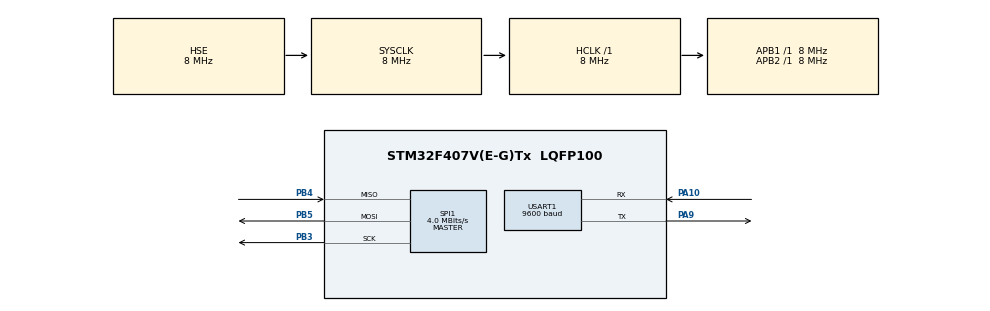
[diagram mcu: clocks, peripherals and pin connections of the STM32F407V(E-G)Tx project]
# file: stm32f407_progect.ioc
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Mcu.Family=STM32F4
Mcu.Name=STM32F407V(E-G)Tx
Mcu.Package=LQFP100
NVIC.PriorityGroup=NVIC_PRIORITYGROUP_4
NVIC.USART1_IRQn=true\:0\:0\:false\:false\:true\:true\:true
PA10.Mode=Asynchronous
PA10.Signal=USART1_RX
PA9.GPIO_PuPd=GPIO_PULLUP
PA9.Mode=Asynchronous
PA9.Signal=USART1_TX
PB3.Mode=Full_Duplex_Master
PB3.Signal=SPI1_SCK
PB4.Mode=Full_Duplex_Master
PB4.Signal=SPI1_MISO
PB5.Mode=Full_Duplex_Master
PB5.Signal=SPI1_MOSI
PC14-OSC32_IN.Mode=LSE-External-Oscillator
PC14-OSC32_IN.Signal=RCC_OSC32_IN
PC15-OSC32_OUT.Mode=LSE-External-Oscillator
PC15-OSC32_OUT.Signal=RCC_OSC32_OUT
PH0-OSC_IN.Mode=HSE-External-Oscillator
PH0-OSC_IN.Signal=RCC_OSC_IN
PH1-OSC_OUT.Mode=HSE-External-Oscillator
PH1-OSC_OUT.Signal=RCC_OSC_OUT
ProjectManager.HeapSize=0x200
ProjectManager.StackSize=0x1000
ProjectManager.TargetToolchain=MDK-ARM V5.27
RCC.48MHZClocksFreq_Value=24000000
RCC.AHBFreq_Value=8000000
RCC.APB1Freq_Value=8000000
RCC.APB1TimFreq_Value=8000000
RCC.APB2Freq_Value=8000000
RCC.APB2TimFreq_Value=8000000
RCC.CortexFreq_Value=8000000
RCC.HCLKFreq_Value=8000000
RCC.HSE_VALUE=8000000
RCC.HSI_VALUE=16000000
RCC.PLLSourceVirtual=RCC_PLLSOURCE_HSE
RCC.RCC_RTC_Clock_Source=RCC_RTCCLKSOURCE_LSE
RCC.RCC_RTC_Clock_SourceVirtual=RCC_RTCCLKSOURCE_LSE
RCC.SYSCLKFreq_VALUE=8000000
RCC.SYSCLKSource=RCC_SYSCLKSOURCE_HSE
RCC.VCOOutputFreq_Value=96000000
SPI1.CalculateBaudRate=4.0 MBits/s
SPI1.Direction=SPI_DIRECTION_2LINES
SPI1.Mode=SPI_MODE_MASTER
SPI1.VirtualType=VM_MASTER
USART1.BaudRate=9600
USART1.VirtualMode=VM_ASYNC
VP_RTC_VS_RTC_Activate.Mode=RTC_Enabled
VP_RTC_VS_RTC_Calendar.Mode=RTC_Calendar
board=custom

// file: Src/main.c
/* USER CODE BEGIN Header */
/**
  ******************************************************************************
  * @file           : main.c
  * @brief          : Main program body
  ******************************************************************************
  * @attention
  *
  * <h2><center>&copy; Copyright (c) 2020 STMicroelectronics.
  * All rights reserved.</center></h2>
  *
  * This software component is licensed by ST under BSD 3-Clause license,
  * the "License"; You may not use this file except in compliance with the
  * License. You may obtain a copy of the License at:
  *                        opensource.org/licenses/BSD-3-Clause
  *
  ******************************************************************************
  */
/* USER CODE END Header */

#include "main.h"

RTC_HandleTypeDef hrtc;

SPI_HandleTypeDef hspi1;

UART_HandleTypeDef huart1;

void SystemClock_Config(void);
static void MX_GPIO_Init(void);
static void MX_RTC_Init(void);
static void MX_SPI1_Init(void);
static void MX_USART1_UART_Init(void);

/* USER CODE BEGIN 0 */
void delay_ms(int32_t nms)
 {
  int32_t temp;
  SysTick->LOAD = 8000*nms;
  SysTick->VAL=0X00;//清空计数器
  SysTick->CTRL=0X01;//使能，减到零是无动作，采用外部时钟源
  do
  {
       temp=SysTick->CTRL;//读取当前倒计数值
  }
     while((temp&0x01)&&(!(temp&(1<<16))));//等待时间到达

     SysTick->CTRL=0x00; //关闭计数器
     SysTick->VAL =0X00; //清空计数器
 }
/* USER CODE END 0 */

int main(void)
{
  /* USER CODE BEGIN 1 */
	uint8_t TxData[]= "Hello World!!!\n";
  /* USER CODE END 1 */

  /* MCU Configuration--------------------------------------------------------*/

  /* Reset of all peripherals, Initializes the Flash interface and the Systick. */
  HAL_Init();

  /* Configure the system clock */
  SystemClock_Config();

  /* Initialize all configured peripherals */
  MX_GPIO_Init();
  MX_RTC_Init();
  MX_SPI1_Init();
  MX_USART1_UART_Init();

  /* Infinite loop */
  /* USER CODE BEGIN WHILE */
  while (1)
  {
		HAL_UART_Transmit(&huart1,TxData,sizeof(TxData),0xffff);
		delay_ms(1000);
    /* USER CODE END WHILE */

  }
}

void SystemClock_Config(void)
{
  RCC_OscInitTypeDef RCC_OscInitStruct = {0};
  RCC_ClkInitTypeDef RCC_ClkInitStruct = {0};
  RCC_PeriphCLKInitTypeDef PeriphClkInitStruct = {0};

  /** Configure the main internal regulator output voltage
  */
  __HAL_RCC_PWR_CLK_ENABLE();
  __HAL_PWR_VOLTAGESCALING_CONFIG(PWR_REGULATOR_VOLTAGE_SCALE1);
  /** Initializes the CPU, AHB and APB busses clocks
  */
  RCC_OscInitStruct.OscillatorType = RCC_OSCILLATORTYPE_HSE|RCC_OSCILLATORTYPE_LSE;
  RCC_OscInitStruct.HSEState = RCC_HSE_ON;
  RCC_OscInitStruct.LSEState = RCC_LSE_ON;
  RCC_OscInitStruct.PLL.PLLState = RCC_PLL_NONE;
  if (HAL_RCC_OscConfig(&RCC_OscInitStruct) != HAL_OK)
  {
    Error_Handler();
  }
  /** Initializes the CPU, AHB and APB busses clocks
  */
  RCC_ClkInitStruct.ClockType = RCC_CLOCKTYPE_HCLK|RCC_CLOCKTYPE_SYSCLK
                              |RCC_CLOCKTYPE_PCLK1|RCC_CLOCKTYPE_PCLK2;
  RCC_ClkInitStruct.SYSCLKSource = RCC_SYSCLKSOURCE_HSE;
  RCC_ClkInitStruct.AHBCLKDivider = RCC_SYSCLK_DIV1;
  RCC_ClkInitStruct.APB1CLKDivider = RCC_HCLK_DIV1;
  RCC_ClkInitStruct.APB2CLKDivider = RCC_HCLK_DIV1;

  if (HAL_RCC_ClockConfig(&RCC_ClkInitStruct, FLASH_LATENCY_0) != HAL_OK)
  {
    Error_Handler();
  }
  PeriphClkInitStruct.PeriphClockSelection = RCC_PERIPHCLK_RTC;
  PeriphClkInitStruct.RTCClockSelection = RCC_RTCCLKSOURCE_LSE;
  if (HAL_RCCEx_PeriphCLKConfig(&PeriphClkInitStruct) != HAL_OK)
  {
    Error_Handler();
  }
}

static void MX_RTC_Init(void)
{

  RTC_TimeTypeDef sTime = {0};
  RTC_DateTypeDef sDate = {0};

  /** Initialize RTC Only
  */
  hrtc.Instance = RTC;
  hrtc.Init.HourFormat = RTC_HOURFORMAT_24;
  hrtc.Init.AsynchPrediv = 127;
  hrtc.Init.SynchPrediv = 255;
  hrtc.Init.OutPut = RTC_OUTPUT_DISABLE;
  hrtc.Init.OutPutPolarity = RTC_OUTPUT_POLARITY_HIGH;
  hrtc.Init.OutPutType = RTC_OUTPUT_TYPE_OPENDRAIN;
  if (HAL_RTC_Init(&hrtc) != HAL_OK)
  {
    Error_Handler();
  }

  /** Initialize RTC and set the Time and Date
  */
  sTime.Hours = 0x0;
  sTime.Minutes = 0x0;
  sTime.Seconds = 0x0;
  sTime.DayLightSaving = RTC_DAYLIGHTSAVING_NONE;
  sTime.StoreOperation = RTC_STOREOPERATION_RESET;
  if (HAL_RTC_SetTime(&hrtc, &sTime, RTC_FORMAT_BCD) != HAL_OK)
  {
    Error_Handler();
  }
  sDate.WeekDay = RTC_WEEKDAY_MONDAY;
  sDate.Month = RTC_MONTH_JANUARY;
  sDate.Date = 0x1;
  sDate.Year = 0x0;

  if (HAL_RTC_SetDate(&hrtc, &sDate, RTC_FORMAT_BCD) != HAL_OK)
  {
    Error_Handler();
  }

}

static void MX_SPI1_Init(void)
{

  /* SPI1 parameter configuration*/
  hspi1.Instance = SPI1;
  hspi1.Init.Mode = SPI_MODE_MASTER;
  hspi1.Init.Direction = SPI_DIRECTION_2LINES;
  hspi1.Init.DataSize = SPI_DATASIZE_8BIT;
  hspi1.Init.CLKPolarity = SPI_POLARITY_LOW;
  hspi1.Init.CLKPhase = SPI_PHASE_1EDGE;
  hspi1.Init.NSS = SPI_NSS_SOFT;
  hspi1.Init.BaudRatePrescaler = SPI_BAUDRATEPRESCALER_2;
  hspi1.Init.FirstBit = SPI_FIRSTBIT_MSB;
  hspi1.Init.TIMode = SPI_TIMODE_DISABLE;
  hspi1.Init.CRCCalculation = SPI_CRCCALCULATION_DISABLE;
  hspi1.Init.CRCPolynomial = 10;
  if (HAL_SPI_Init(&hspi1) != HAL_OK)
  {
    Error_Handler();
  }

}

static void MX_USART1_UART_Init(void)
{

  huart1.Instance = USART1;
  huart1.Init.BaudRate = 9600;
  huart1.Init.WordLength = UART_WORDLENGTH_8B;
  huart1.Init.StopBits = UART_STOPBITS_1;
  huart1.Init.Parity = UART_PARITY_NONE;
  huart1.Init.Mode = UART_MODE_TX_RX;
  huart1.Init.HwFlowCtl = UART_HWCONTROL_NONE;
  huart1.Init.OverSampling = UART_OVERSAMPLING_16;
  if (HAL_UART_Init(&huart1) != HAL_OK)
  {
    Error_Handler();
  }

}

static void MX_GPIO_Init(void)
{

  /* GPIO Ports Clock Enable */
  __HAL_RCC_GPIOC_CLK_ENABLE();
  __HAL_RCC_GPIOH_CLK_ENABLE();
  __HAL_RCC_GPIOA_CLK_ENABLE();
  __HAL_RCC_GPIOB_CLK_ENABLE();

}

void Error_Handler(void)
{
}

/************************ (C) COPYRIGHT STMicroelectronics *****END OF FILE****/
